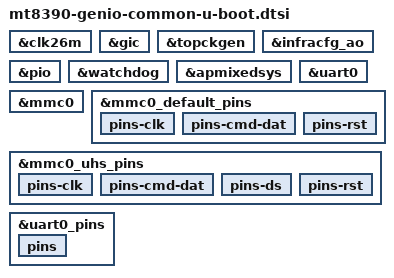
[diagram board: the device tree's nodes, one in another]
// SPDX-License-Identifier: (GPL-2.0-only OR MIT)
/*
 * Copyright (c) 2026 BayLibre SAS
 * Author: Julien Stephan <jstephan@baylibre.com>
 * Author: Carlo Caione <ccaione@baylibre.com>
 */

&clk26m {
	bootph-pre-ram;
};

&gic {
	/* Retain the eMMC interrupt parent even though SPL uses polling. */
	bootph-pre-ram;
};

&topckgen {
	bootph-pre-ram;
};

&infracfg_ao {
	bootph-pre-ram;
};

&pio {
	bootph-pre-ram;
};

&watchdog {
	bootph-pre-ram;
};

&apmixedsys {
	bootph-pre-ram;
};

&uart0 {
	bootph-pre-ram;
};

&mmc0 {
	bootph-pre-ram;
};

&mmc0_default_pins {
	bootph-pre-ram;

	pins-clk {
		bootph-pre-ram;
	};

	pins-cmd-dat {
		bootph-pre-ram;
	};

	pins-rst {
		bootph-pre-ram;
	};
};

&mmc0_uhs_pins {
	bootph-pre-ram;

	pins-clk {
		bootph-pre-ram;
	};

	pins-cmd-dat {
		bootph-pre-ram;
	};

	pins-ds {
		bootph-pre-ram;
	};

	pins-rst {
		bootph-pre-ram;
	};
};

&uart0_pins {
	bootph-pre-ram;

	pins {
		bootph-pre-ram;
	};
};
